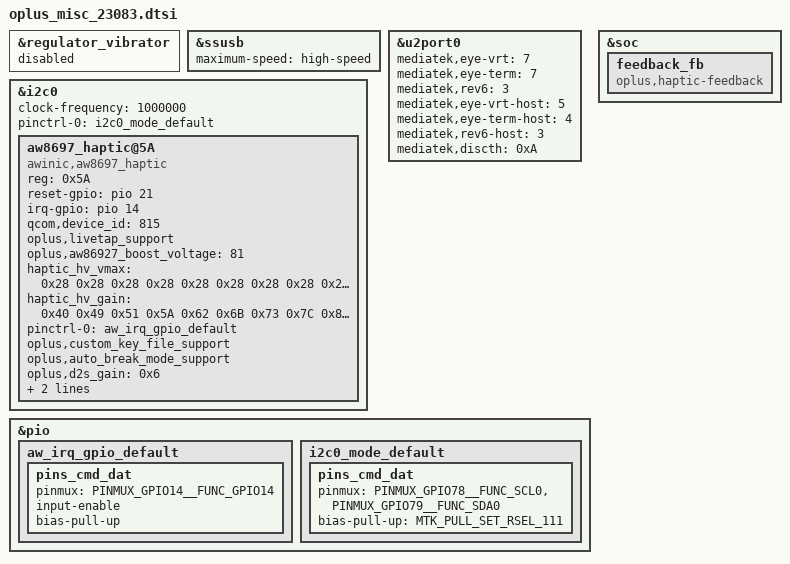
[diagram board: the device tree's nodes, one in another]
// SPDX-License-Identifier: GPL-2.0-only
/*
* Copyright (C) 2021-2020 Oplus. All rights reserved.
*/
#include <dt-bindings/iio/mt635x-auxadc.h>
#include <dt-bindings/pinctrl/mt6373-pinfunc.h>
#include <dt-bindings/pinctrl/mt65xx.h>


/* charge start */
&regulator_vibrator{
	status = "disabled";
};

&ssusb {
	maximum-speed = "high-speed";
};

&u2port0 {
	mediatek,eye-vrt = <7>;
	mediatek,eye-term = <7>;
	mediatek,rev6 = <3>;
	mediatek,eye-vrt-host = <5>;
	mediatek,eye-term-host = <4>;
	mediatek,rev6-host = <3>;
	mediatek,discth = <0xA>;
};

&i2c0 {
	status = "okay";
	clock-frequency = <1000000>;

	// AWINIC AW8697 Haptic
	aw8697_haptic@5A {
		status = "okay";
		compatible = "awinic,aw8697_haptic";
		reg = <0x5A>;
		reset-gpio = <&pio 21 0x00>;
		irq-gpio = <&pio 14 0x00>;
		qcom,device_id = <815>;
		oplus,livetap_support;
		oplus,aw86927_boost_voltage = <81>; /* 0x51 */

		haptic_hv_vmax = /bits/ 8 < 0x28 0x28 0x28 0x28 0x28 0x28 0x28 0x28 0x2A 0x31 0x38 0x3F 0x46 0x4C 0x51 0x51 0x51 >;
		haptic_hv_gain = /bits/ 8 < 0x40 0x49 0x51 0x5A 0x62 0x6B 0x73 0x7C 0x80 0x80 0x80 0x80 0x80 0x80 0x80 0x80 0x80 >;

		pinctrl-names = "default";
		pinctrl-0 = <&aw_irq_gpio_default>;
		oplus,custom_key_file_support;
		oplus,auto_break_mode_support;
		oplus,d2s_gain = /bits/ 8 <0x6>;
		oplus,brk_time = /bits/ 8 <0x5>;
		oplus,brk_gain = /bits/ 8 <0x7>;
	};
};

&i2c0 {
	pinctrl-names = "default";
	pinctrl-0 = <&i2c0_mode_default>;
};

&pio{
	aw_irq_gpio_default: aw_irq_gpio_default {
		pins_cmd_dat {
			pinmux = <PINMUX_GPIO14__FUNC_GPIO14>;
			input-enable;
			bias-pull-up;
		};
	};

	i2c0_mode_default: i2c0_mode_default {
		pins_cmd_dat {
			pinmux = <PINMUX_GPIO78__FUNC_SCL0>,
				 <PINMUX_GPIO79__FUNC_SDA0>;
			bias-pull-up = <MTK_PULL_SET_RSEL_111>;
		};
	};
};

&soc {
	feedback_fb: feedback_fb {
		compatible = "oplus,haptic-feedback";
	};
};
